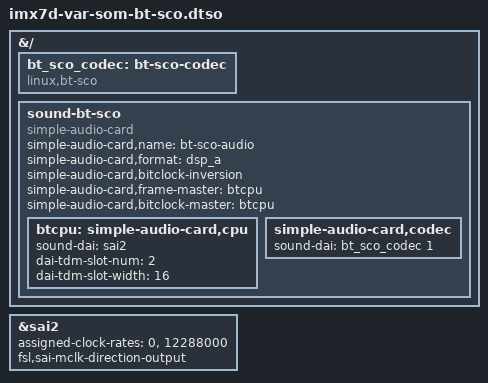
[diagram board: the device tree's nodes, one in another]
// SPDX-License-Identifier: GPL-2.0+ OR MIT

/dts-v1/;
/plugin/;

&{/} {
	bt_sco_codec: bt-sco-codec {
		#sound-dai-cells = <1>;
		compatible = "linux,bt-sco";
	};

	sound-bt-sco {
		compatible = "simple-audio-card";
		simple-audio-card,name = "bt-sco-audio";
		simple-audio-card,format = "dsp_a";
		simple-audio-card,bitclock-inversion;
		simple-audio-card,frame-master = <&btcpu>;
		simple-audio-card,bitclock-master = <&btcpu>;

		btcpu: simple-audio-card,cpu {
			sound-dai = <&sai2>;
			dai-tdm-slot-num = <2>;
			dai-tdm-slot-width = <16>;
		};

		simple-audio-card,codec {
			sound-dai = <&bt_sco_codec 1>;
		};
	};
};

&sai2 {
	assigned-clock-rates = <0>, <12288000>;
	fsl,sai-mclk-direction-output;
	status = "okay";
};
